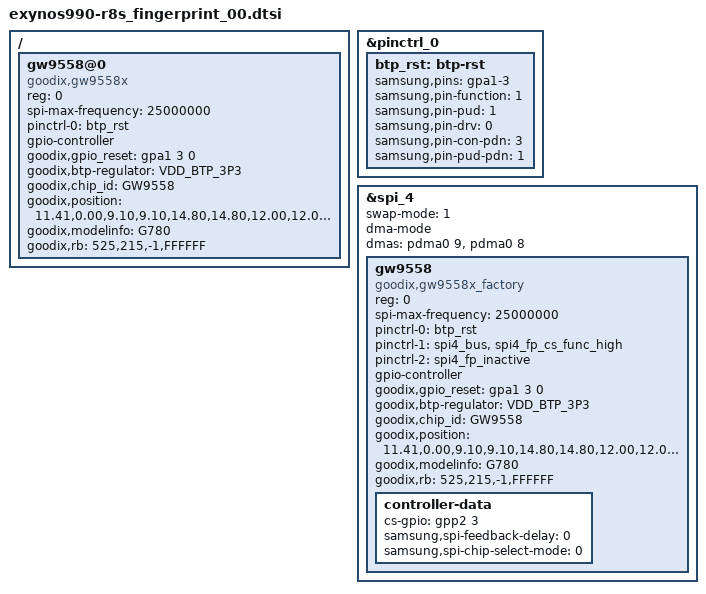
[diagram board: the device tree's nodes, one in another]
/*
 * Copyright (c) 2012-2013, The Linux Foundation. All rights reserved.
 *
 * This program is free software; you can redistribute it and/or modify
 * it under the terms of the GNU General Public License version 2 and
 * only version 2 as published by the Free Software Foundation.
 *
 * This program is distributed in the hope that it will be useful,
 * but WITHOUT ANY WARRANTY; without even the implied warranty of
 * MERCHANTABILITY or FITNESS FOR A PARTICULAR PURPOSE.  See the
 * GNU General Public License for more details.
 */

&pinctrl_0 {
	btp_rst: btp-rst {
		samsung,pins = "gpa1-3";
		samsung,pin-function = <1>;
		samsung,pin-pud = <1>;
		samsung,pin-drv = <0>;
		samsung,pin-con-pdn = <3>;
		samsung,pin-pud-pdn = <1>;
	};
};

&spi_4 {
	status = "okay";

	swap-mode = <1>;
	dma-mode;
	dmas = <&pdma0 9 &pdma0 8>;
	dma-names = "tx", "rx";

	gw9558 {
		compatible = "goodix,gw9558x_factory";
		reg = <0>;
		spi-max-frequency = <25000000>;

		pinctrl-names = "default", "pins_poweron", "pins_poweroff";
		pinctrl-0 = <&btp_rst>;
		pinctrl-1 = <&spi4_bus &spi4_fp_cs_func_high>;
		pinctrl-2 = <&spi4_fp_inactive>;

		gpio-controller;
		#gpio-cells = <2>;

		goodix,gpio_reset = <&gpa1 3 0>;
		goodix,btp-regulator = "VDD_BTP_3P3";
		goodix,chip_id = "GW9558";
		goodix,position = "11.41,0.00,9.10,9.10,14.80,14.80,12.00,12.00,5.00";
		goodix,modelinfo = "G780";
		goodix,rb = "525,215,-1,FFFFFF";

		controller-data {
			cs-gpio = <&gpp2 3 0>;
			samsung,spi-feedback-delay = <0>;
			samsung,spi-chip-select-mode = <0>;
		};
	};
};

/ {
	fragment@model {
		target-path = "/";
		__overlay__ {
			gw9558@0 {
				compatible = "goodix,gw9558x";
				reg = <0>;
				spi-max-frequency = <25000000>;

				pinctrl-names = "default";
				pinctrl-0 = <&btp_rst>;

				gpio-controller;
				#gpio-cells = <2>;

				goodix,gpio_reset = <&gpa1 3 0>;
				goodix,btp-regulator = "VDD_BTP_3P3";
				goodix,chip_id = "GW9558";
				goodix,position = "11.41,0.00,9.10,9.10,14.80,14.80,12.00,12.00,5.00";
				goodix,modelinfo = "G780";
				goodix,rb = "525,215,-1,FFFFFF";
			};
		};
	};
};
